# nrf7140_application register map
Vendor: Nordic Semiconductor; Series: nRF71; File version: 1
CPU: CM33 r0p4, little endian, MPU, FPU, 3 interrupt priority bits, 480 interrupts, 8 SAU regions
Registers are 32-bit, read-write, reset 0x0 unless marked. A register's access mark holds for its fields unless they carry their own. Offsets are from the block's base; [hi:lo] are bit positions; lines under a group give offsets from that group; {n}, {i} and the like mark numbered series; 'fields as' and 'values as' point back to an identical list.

## PCGCS000_S — PCGCSlave 0
Base 0x5200B000
Same registers: PCGCS010_S 0x5201B000
{0xC00+4i} PENALTY[{i}] (i=0..1) reset 0xFFFFFFFC — Description collection: Penalty level for power/clock pair n. When FULL_PCP_ZERO feature is not supported, PENALTY[0] address overlaps the PENALTY0 address and register description for PENALTY[0] is not valid.
  [1:0] PENALTY — Penalty level
0xC00 PENALTY0 (alternate view of PENALTY[*]) — Penalty level for power/clock pair 0. The register description is valid only when FULL_PCP_ZERO feature is not supported
  [1:0] PENALTY ro — Penalty level
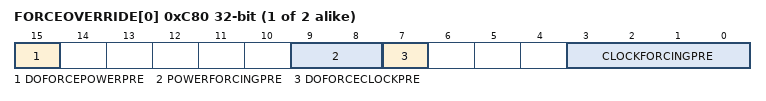
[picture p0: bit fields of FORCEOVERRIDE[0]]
{0xC80+4i} FORCEOVERRIDE[{i}] (i=0..1) — Description collection: Force override of power/clock pair n.
  [15] DOFORCEPOWERPRE, [9:8] POWERFORCINGPRE, [7] DOFORCECLOCKPRE, [3:0] CLOCKFORCINGPRE

## GLOBAL_PCGCSBUS_NS — PCGCSlave
Base 0x4900CF00; alternate view of GLOBAL_GFXPLLPM_NS
Registers as PCGCS000_S.

## GLOBAL_GFXPLLPM_NS — AUXPM
Base 0x4900C000
Same registers: GLOBAL_AUDIOPLLPM_NS 0x4F968000, GLOBAL_CANPLLPM_S 0x5F8C2000, GLOBAL_AUDIOPLLPM_S 0x5F968000
0x20 TASKS_START wo — Request power up
  [0] TASKS_START
    1=Trigger task
0x24 TASKS_STOP wo — Stop requesting power up
  [0] TASKS_STOP
    1=Trigger task
0x110 EVENTS_SETTLED — LDO settled
  [0] EVENTS_SETTLED
    0=NotGenerated (Event not generated); 1=Generated (Event generated)
0x300 INTEN — Enable or disable interrupt
  [4] SETTLED — Enable or disable interrupt for event SETTLED
    0=Disabled; 1=Enabled
0x304 INTENSET — Enable interrupt
  [4] SETTLED — Write '1' to enable interrupt for event SETTLED
    on read: 0=Disabled (Read: Disabled); 1=Enabled (Read: Enabled) | on write: 1=Set (Enable)
0x308 INTENCLR — Disable interrupt
  [4] SETTLED — Write '1' to disable interrupt for event SETTLED
    on read: 0=Disabled (Read: Disabled); 1=Enabled (Read: Enabled) | on write: 1=Clear (Disable)
0x30C INTPEND ro — Pending interrupts
  [4] SETTLED — Read pending status of interrupt for event SETTLED
    on read: 0=NotPending (Read: Not pending); 1=Pending (Read: Pending)
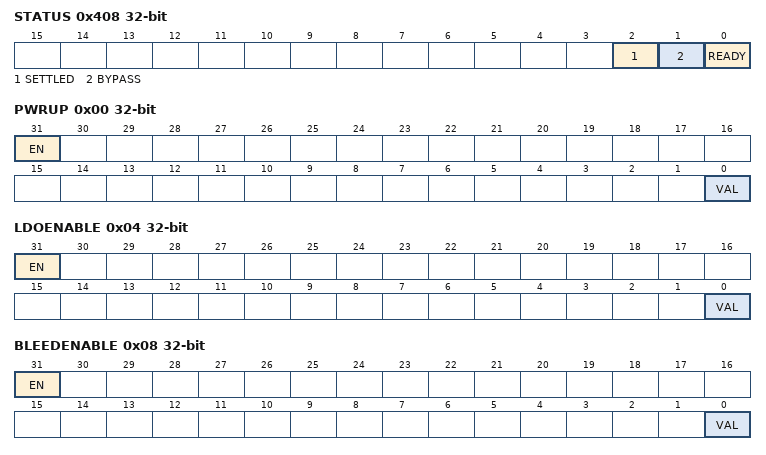
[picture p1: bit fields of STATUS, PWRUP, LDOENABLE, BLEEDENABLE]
0x408 STATUS ro — Status of AuxPm
  [2] SETTLED — LDO settled
    0=NotSettled (AuxPm not settled); 1=Settled (AuxPm settled)
  [1] BYPASS — Bypassing vref filter for startup boost
    0=NotBypass (VrefFilt not bypassed); 1=Bypass (VrefFilt bypassed)
  [0] READY — AuxPm powered up
    0=PowerDown (AuxPm powered down); 1=Powered (AuxPm powered up)
0x420 CONFIG group — Unspecified
  0x00 STARTUPTIME reset 0x18 — Time from pwrup to ready signal (0us-3us)
    [5:0] VAL — Timer value
      0=Min (0 us); 24=Default (1.5 us); 48=Max (3 us)
  0x04 SHUTDOWNTIME reset 0x18 — Time from shutdown until to ready signal is deasserted (0us-3us)
    fields as CONFIG.STARTUPTIME
  0x08 BYPASSTIME reset 0x70 — Time from ready until bypass vref turned off (7us-40us)
    [9:0] VAL — Timer value
      112=Min (7 us); 112=Default (7 us); 0x280=Max (40 us)
  0x0C SETLTIME reset 0x18 — Time from bypass turned off to settled (0us-3us)
    fields as CONFIG.STARTUPTIME
0x450 TRIM group — Unspecified
  0x00 VREFPM — Reference voltage trimming. Equals output voltage
    [2:0] VAL — Voltage trimming value.
      0=Val800mV (800 mV); 1=Val825mV (825 mV); 2=Val850mV (850 mV); 3=Val900mV (900 mV); 4=Val600mV (600 mV); 5=Val650mV (650 mV); 6=Val700mV (700 mV); 7=Val750mV (750 mV)
0x4F0 MIRROR — Enable LOCK for mirrored registers
  [0] LOCK — Lock for mirrored registers
    0=Disabled (Lock disabled); 1=Enabled (Lock enabled)
0x580 OVERRIDE group — Unspecified
  0x00 PWRUP — Override the pwrup to the analog module
    [31] EN — Enable the override
      0=Disabled (Override is disabled); 1=Enabled (Override is enabled)
    [0] VAL — Override value for the signal
  0x04 LDOENABLE — Override the LDO enable to the analog module
    fields as OVERRIDE.PWRUP
  0x08 BLEEDENABLE — Override the bleed enable to the analog module
    fields as OVERRIDE.PWRUP
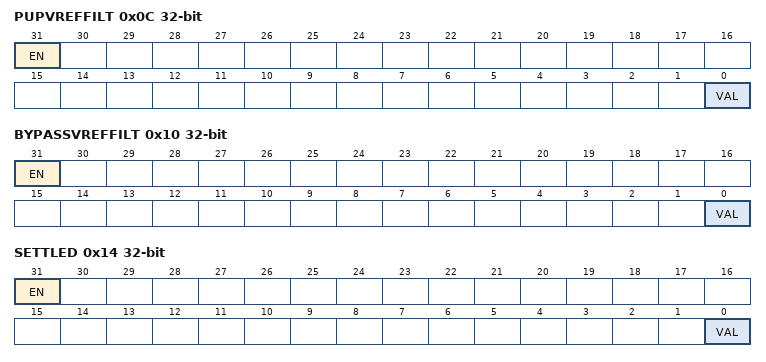
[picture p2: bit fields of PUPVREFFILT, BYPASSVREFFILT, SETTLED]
  0x0C PUPVREFFILT — Override the vref filter enable to the analog module
    fields as OVERRIDE.PWRUP
  0x10 BYPASSVREFFILT — Override the vref bypass to the analog module
    fields as OVERRIDE.PWRUP
  0x14 SETTLED — Override the SETTLED from the digital part
    fields as OVERRIDE.PWRUP
0x680 DFT group — Unspecified
  0x00 ATB0CONFIG — Analog Test Bus 0 (ATB0) configuration
    [31] EN
      0=Disabled (Analog test bus is disabled); 1=Enabled (Analog test bus is enabled)
  0x04 ATB1CONFIG — Analog Test Bus 1 (ATB1) configuration
    fields as DFT.ATB0CONFIG
